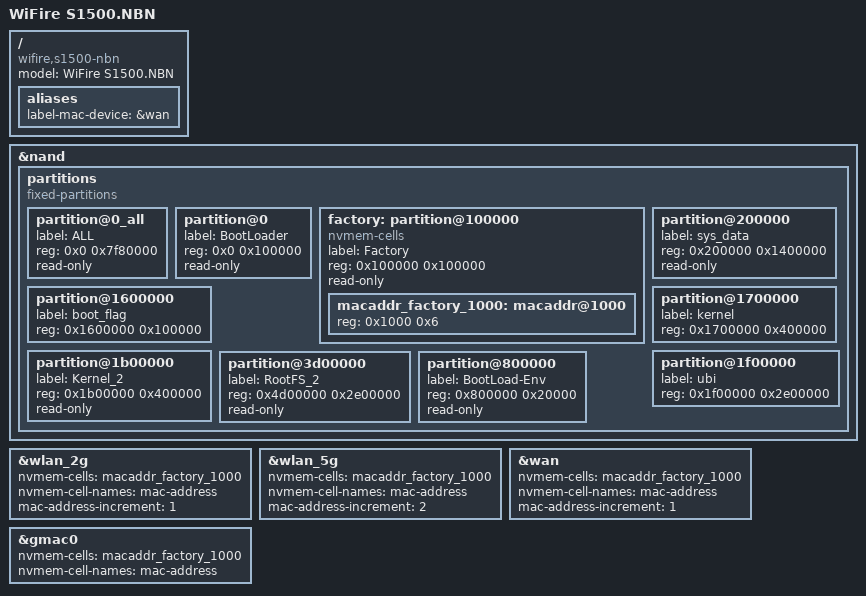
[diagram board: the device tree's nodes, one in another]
// SPDX-License-Identifier: GPL-2.0-or-later OR MIT

#include "mt7621_sercomm_s1500.dtsi"

/ {
	compatible = "wifire,s1500-nbn", "mediatek,mt7621-soc";
	model = "WiFire S1500.NBN";

	aliases {
		label-mac-device = &wan;
	};
};

&nand { // 128 MiB
	status = "okay";

	partitions { // Требуется узнать разметку WiFire S1500.NBN
		compatible = "fixed-partitions";
		#address-cells = <1>;
		#size-cells = <1>;

		partition@0_all {
			label = "ALL";
			reg = <0x0 0x7f80000>;
			read-only;
		};

		partition@0 {
			label = "BootLoader";
			reg = <0x0 0x100000>;
			read-only;
		};

		factory: partition@100000 {
			label = "Factory"; // RF-EEPROM
			reg = <0x100000 0x100000>;
			read-only;
		};

		partition@200000 {
			label = "sys_data";
			reg = <0x200000 0x1400000>;
			read-only;
		};

		partition@1600000 {
			label = "boot_flag";
			reg = <0x1600000 0x100000>;
		};

		partition@1700000 {
			label = "kernel"; // Kernel_1
			reg = <0x1700000 0x400000>;
		};

		partition@1b00000 {
			label = "Kernel_2";
			reg = <0x1b00000 0x400000>;
			read-only;
		};

		partition@1f00000 {
			label = "ubi"; // RootFS_1
			reg = <0x1f00000 0x2e00000>;
		};

		partition@3d00000 {
			label = "RootFS_2";
			reg = <0x4d00000 0x2e00000>;
			read-only;
		};

		/*
		 * 512 kB bad block reserved
		 * 7f80000 bbt 0x80000?
		 */

		partition@800000 { // U-boot Environment
			label = "BootLoad-Env";
			reg = <0x800000 0x20000>;
			read-only;
		};
	};
};

&wlan_2g {
	nvmem-cells = <&macaddr_factory_1000>;
	nvmem-cell-names = "mac-address";
	mac-address-increment = <1>;
};

&wlan_5g {
	nvmem-cells = <&macaddr_factory_1000>;
	nvmem-cell-names = "mac-address";
	mac-address-increment = <2>;
};

&wan {
	nvmem-cells = <&macaddr_factory_1000>;
	nvmem-cell-names = "mac-address";
	mac-address-increment = <1>;
};

&gmac0 {
	nvmem-cells = <&macaddr_factory_1000>;
	nvmem-cell-names = "mac-address";
};

&factory {
	compatible = "nvmem-cells";
	#address-cells = <1>;
	#size-cells = <1>;

	macaddr_factory_1000: macaddr@1000 {
		reg = <0x1000 0x6>;
	};
};
